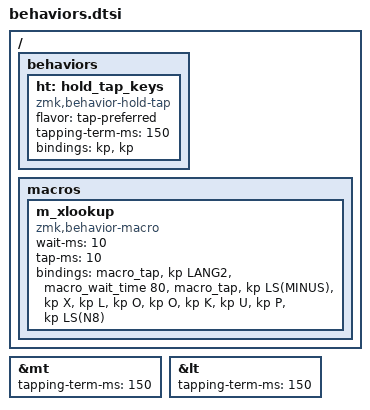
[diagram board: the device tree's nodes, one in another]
/*
 * 独自ビヘイビア（マクロ・ホールドタップなど）
 *   ここで定義したものはレイヤーやコンボから &名前 で使える。
 */

/ {
    behaviors {
        /* 長押しと短押しで別のキー組み合わせを送るホールドタップ
           使い方: &ht <長押し> <短押し>   例: &ht LC(SPACE) LS(SPACE) */
        ht: hold_tap_keys {
            compatible = "zmk,behavior-hold-tap";
            #binding-cells = <2>;
            flavor = "tap-preferred";
            tapping-term-ms = <150>;
            bindings = <&kp>, <&kp>;
        };
    };

    macros {
        /* 英数入力に切り替えてから "=xlookup(" を入力するマクロ
           ※ PC側が JIS 配列設定なので、記号は JIS のキー位置で指定している
              "=" … LS(MINUS)   "(" … LS(N8)
           英数への切り替えが効かない場合は LANG2 を INT5（無変換）や
           GRAVE（半角/全角）に変えて試す */
        m_xlookup: m_xlookup {
            compatible = "zmk,behavior-macro";
            #binding-cells = <0>;
            wait-ms = <10>;
            tap-ms = <10>;
            bindings = <&macro_tap &kp LANG2>
                     , <&macro_wait_time 80>
                     , <&macro_tap
                &kp LS(MINUS) &kp X &kp L &kp O &kp O &kp K &kp U &kp P &kp LS(N8)>;
        };
    };
};

/* 組み込みの mod-tap / layer-tap も長押し判定を150msに揃える */
&mt { tapping-term-ms = <150>; };
&lt { tapping-term-ms = <150>; };
